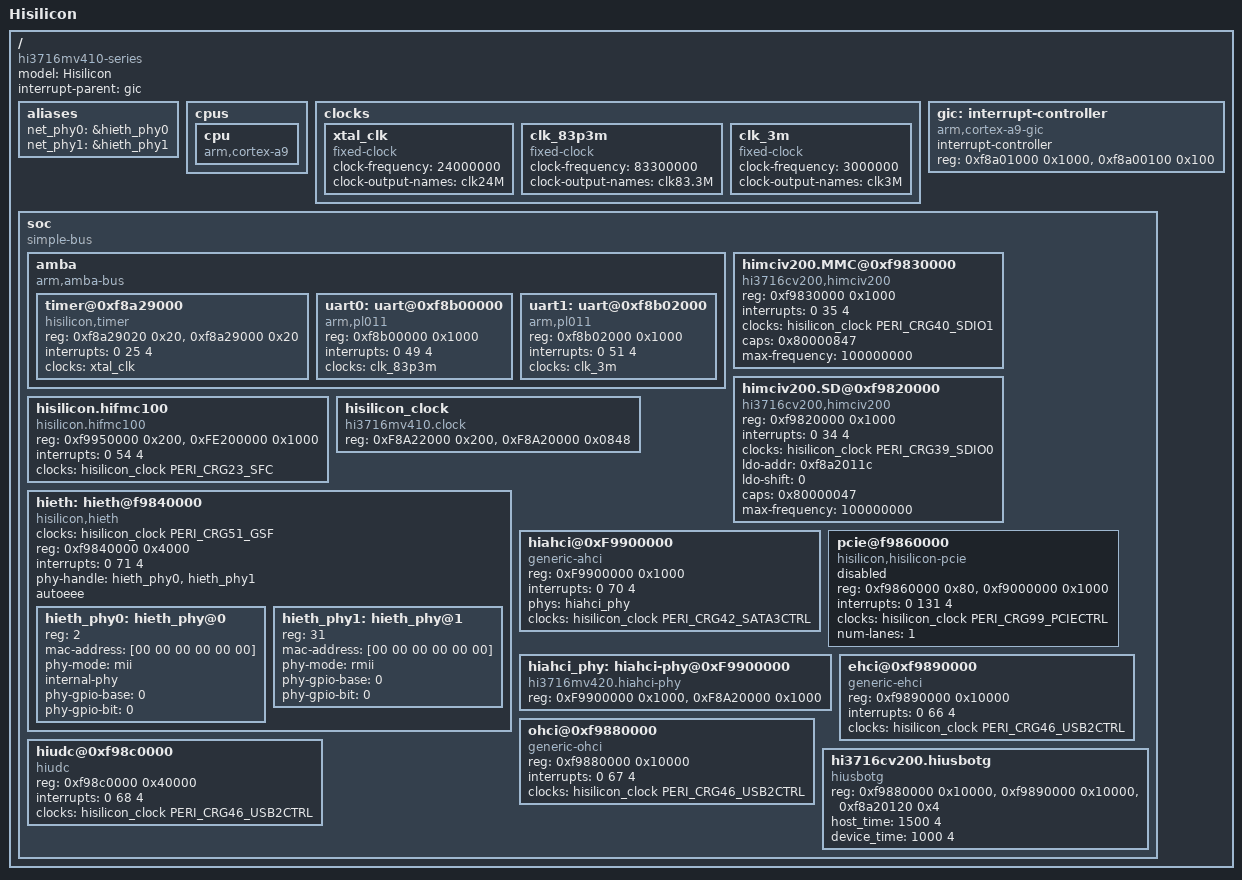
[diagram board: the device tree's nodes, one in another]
/dts-v1/;

#include <dt-bindings/clock/hi3716cv200-clock.h>

/ {
	model = "Hisilicon";
	compatible = "hi3716mv410-series";
	#address-cells = <1>;
	#size-cells = <1>;
	interrupt-parent = <&gic>;

	aliases {
		net_phy0 = &hieth_phy0;
		net_phy1 = &hieth_phy1;
	};

	cpus {
		#address-cells = <1>;
		#size-cells = <0>;

		cpu {
			device_type = "cpu";
			compatible = "arm,cortex-a9";
		};
	};

	clocks {
		xtal_clk: xtal_clk {
			compatible = "fixed-clock";
			#clock-cells = <0>;
			clock-frequency = <24000000>;
			clock-output-names = "clk24M";
		};

		clk_83p3m: clk_83p3m {
			compatible = "fixed-clock";
			#clock-cells = <0>;
			clock-frequency = <83300000>;
			clock-output-names = "clk83.3M";
		};

		clk_3m: clk_3m{
			compatible = "fixed-clock";
			#clock-cells = <0>;
			clock-frequency = <3000000>;
			clock-output-names = "clk3M";
		};
	};

	gic: interrupt-controller {
		compatible = "arm,cortex-a9-gic";
		#interrupt-cells = <3>;
		#address-cells = <0>;
		interrupt-controller;
		reg = <0xf8a01000 0x1000>,
		      <0xf8a00100 0x100>;
	};

	soc {
		#address-cells = <1>;
		#size-cells = <1>;
		compatible = "simple-bus";
		device_type = "soc";
		ranges = <0x0 0x0 0xffffffff>;

		amba {
			compatible = "arm,amba-bus";
			#address-cells = <1>;
			#size-cells = <1>;
			ranges;

			/*
			 * Used for clocksource and local timer
			 */
			timer@0xf8a29000 {
				compatible = "hisilicon,timer";
				reg = <0xf8a29020 0x20>, /* clocksource */
				      <0xf8a29000 0x20>;
				interrupts = <0 25 4>;
				clocks = <&xtal_clk>;
				clock-names = "apb_pclk";
			};

			uart0: uart@0xf8b00000 {
				compatible = "arm,pl011", "arm,primecell";
				reg = <0xf8b00000 0x1000>;
				interrupts = <0 49 4>;
				clocks = <&clk_83p3m>;
				clock-names = "apb_pclk";
			};

			uart1: uart@0xf8b02000 {
				compatible = "arm,pl011", "arm,primecell";
				reg = <0xf8b02000 0x1000>;
				interrupts = <0 51 4>;
				clocks = <&clk_3m>;
				clock-names = "apb_pclk";
			};
		};

		himciv200.MMC@0xf9830000 {
			compatible = "hi3716cv200,himciv200";
			reg = <0xf9830000 0x1000>;
			interrupts = <0 35 4>;

			clocks = <&hisilicon_clock PERI_CRG40_SDIO1>;
			clock-names = "clk";

			caps = <0x80000847>;
			max-frequency = <100000000>;
		};

		himciv200.SD@0xf9820000 {
			compatible = "hi3716cv200,himciv200";
			reg = <0xf9820000 0x1000>;
			interrupts = <0 34 4>;

			clocks = <&hisilicon_clock PERI_CRG39_SDIO0>;
			clock-names = "clk";

			ldo-addr  = <0xf8a2011c>;
			ldo-shift = <0>;

			caps = <0x80000047>;
			max-frequency = <100000000>;
		};

		hisilicon.hifmc100 {
			compatible = "hisilicon.hifmc100";
			reg = <0xf9950000 0x200>,<0xFE200000 0x1000>;
			interrupts = <0 54 4>;

			clocks = <&hisilicon_clock PERI_CRG23_SFC>;
			clock-names = "clk";
		};

		hisilicon_clock: hisilicon_clock {
			compatible = "hi3716mv410.clock";
			reg = <0xF8A22000 0x200>, <0xF8A20000 0x0848>;
			#clock-cells = <1>;
		};

		hieth: hieth@f9840000 {
			compatible = "hisilicon,hieth";
			clocks = <&hisilicon_clock PERI_CRG51_GSF>;
			clock-names = "clk";
			reg = <0xf9840000 0x4000>;
			interrupts = <0 71 4>;
			phy-handle = <&hieth_phy0 &hieth_phy1>;
			autoeee;
			#address-cells = <1>;
			#size-cells = <0>;

			hieth_phy0: hieth_phy@0 {
				reg = <2>;
				mac-address = [00 00 00 00 00 00];
				phy-mode = "mii";
				internal-phy;
				phy-gpio-base = <0>;
				phy-gpio-bit = <0>;
			};

			hieth_phy1: hieth_phy@1{
				reg = <31>;
				mac-address = [00 00 00 00 00 00];
				phy-mode = "rmii";
				phy-gpio-base = <0>;
				phy-gpio-bit = <0>;
			};
		};

		/* hiahci@0xF9900000 and pcie@f9860000 , select 1 of 2 */
		hiahci@0xF9900000 {
			compatible = "generic-ahci";
			reg = <0xF9900000 0x1000>;
			interrupts = <0 70 4>;

			phys = <&hiahci_phy>;
			phy-names = "sata-phy";

			clocks = <&hisilicon_clock PERI_CRG42_SATA3CTRL>;
			clock-names = "clk";
			status = "okay";
		};

		pcie@f9860000 {
			compatible = "hisilicon,hisilicon-pcie","snps,dw-pcie";
			reg = <0xf9860000 0x80>,<0xf9000000 0x1000>;
			interrupts = <0 131 4>;

			clocks = <&hisilicon_clock PERI_CRG99_PCIECTRL>;
			clock-names = "clk";

			#address-cells = <3>;
			#size-cells = <2>;
			device_type = "pci";
			ranges=<0x00000800 0 0xc8100000 0xc8100000 0 0x00100000
					0x81000000 0 0xc8000000 0xc8000000 0 0x00100000
					0x82000000 0 0xc0000000 0xc0000000 0 0x08000000>;
			num-lanes = <1>;
			status = "disabled";
		};

		hiahci_phy: hiahci-phy@0xF9900000 {
			compatible = "hi3716mv420.hiahci-phy";
			reg = <0xF9900000 0x1000>,<0xF8A20000 0x1000>;
			#phy-cells = <0>;
		};

		ehci@0xf9890000 {
			compatible = "generic-ehci";
			reg = <0xf9890000 0x10000>;
			interrupts = <0 66 4>;

			clocks = <&hisilicon_clock PERI_CRG46_USB2CTRL>;
			clock-names = "clk";
		};

		ohci@0xf9880000 {
			compatible = "generic-ohci";
			reg = <0xf9880000 0x10000>;
			interrupts = <0 67 4>;

			clocks = <&hisilicon_clock PERI_CRG46_USB2CTRL>;
			clock-names = "clk";
		};

		hiudc@0xf98c0000 {
			compatible = "hiudc";
			reg = <0xf98c0000 0x40000>;
			interrupts = <0 68 4>;

			clocks = <&hisilicon_clock PERI_CRG46_USB2CTRL>;
			clock-names = "clk";
		};

		hi3716cv200.hiusbotg {
			compatible = "hiusbotg";
			reg = <0xf9880000 0x10000>,<0xf9890000 0x10000>,<0xf8a20120 0x4>;
			host_time = <1500 4>;
			device_time = <1000 4>;
		};
	};
};
